# STM32H730xxQ register map
File version: 1.0
Registers are 32-bit, read-write, reset 0x0 unless marked. A register's access mark holds for its fields unless they carry their own. Offsets are from the block's base; [hi:lo] are bit positions; {n}, {i} and the like mark numbered series; 'fields as' and 'values as' point back to an identical list.

## CRYP — Crypto Processor
Base 0x48021000
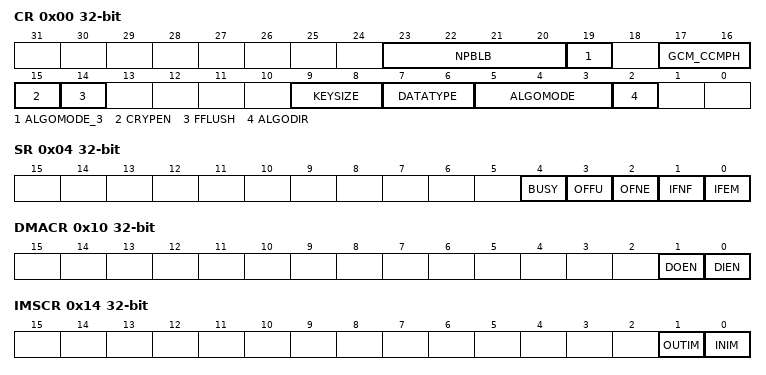
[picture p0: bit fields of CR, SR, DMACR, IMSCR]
0x00 CR — CRYP control register
  [23:20] NPBLB, [19] ALGOMODE_3, [17:16] GCM_CCMPH, [15] CRYPEN, [14] FFLUSH, [9:8] KEYSIZE, [7:6] DATATYPE, [5:3] ALGOMODE, [2] ALGODIR
0x04 SR — CRYP status register
  [4] BUSY, [3] OFFU, [2] OFNE, [1] IFNF, [0] IFEM
0x08 DIN — CRYP data input register
0x0C DOUT — CRYP data output register
0x10 DMACR — CRYP DMA control register
  [1] DOEN, [0] DIEN
0x14 IMSCR — CRYP interrupt mask set/clear register
  [1] OUTIM, [0] INIM
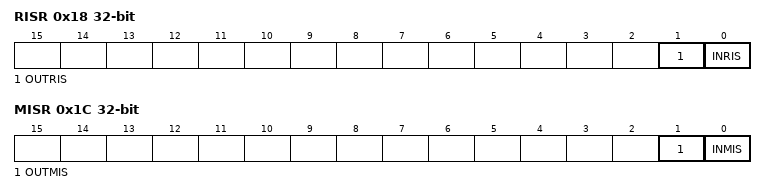
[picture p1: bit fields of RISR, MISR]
0x18 RISR — CRYP raw interrupt status register
  [1] OUTRIS, [0] INRIS
0x1C MISR — CRYP masked interrupt status register
  [1] OUTMIS, [0] INMIS
{0x20+8i} K{i}LR (i=0..3) — CRYP key left register {i}
{0x24+8i} K{i}RR (i=0..3) — CRYP key right register {i}
0x40 IV0LR — CRYP initialization vector left-word register 0
0x44 IV0RR — CRYP initialization vector right-word register 0
0x48 IV1LR — CRYP initialization vector left-word register 1
0x4C IV1RR — CRYP initialization vector right-word register 1
{0x50+4i} CSGCMCCM{i}R (i=0..7) — CRYP GCM/GMAC or CCM/CMAC context swap register {i}
{0x70+4i} CSGCM{i}R (i=0..7) — CRYP GCM/GMAC context swap register {i}

## HASH
Base 0x48021400
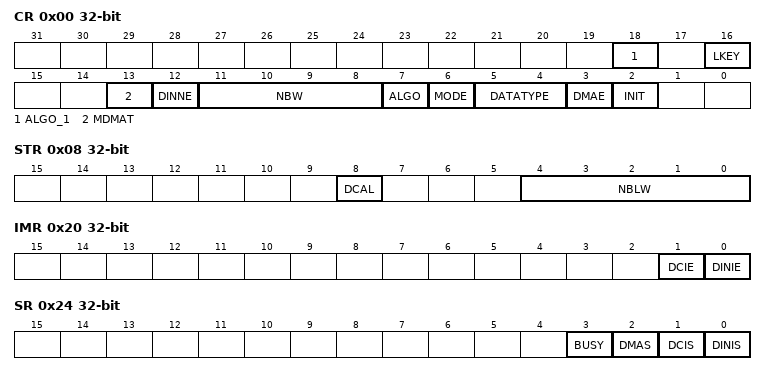
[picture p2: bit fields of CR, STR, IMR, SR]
0x00 CR — HASH control register
  [18] ALGO_1, [16] LKEY, [13] MDMAT, [12] DINNE, [11:8] NBW, [7] ALGO, [6] MODE, [5:4] DATATYPE, [3] DMAE, [2] INIT
0x04 DIN — HASH data input register
0x08 STR — HASH start register
  [8] DCAL, [4:0] NBLW
{0xC+4i} HR{i} (i=0..4) — HASH digest registers
0x20 IMR — HASH interrupt enable register
  [1] DCIE, [0] DINIE
0x24 SR — HASH status register
  [3] BUSY, [2] DMAS, [1] DCIS, [0] DINIS
{0xF8+4i} CSR{i} (i=0..53) — HASH context swap registers
{0x310+4i} DIGEST_HR{i} (i=0..7) — HASH digest registers

## RNG
Base 0x48021800
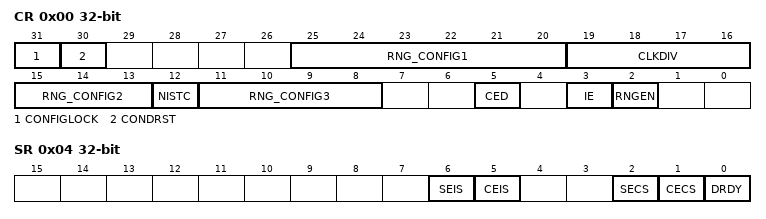
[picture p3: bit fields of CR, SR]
0x00 CR — RNG control register
  [31] CONFIGLOCK
  [30] CONDRST
  [25:20] RNG_CONFIG1
  [19:16] CLKDIV
    0=BY_1 (No clock division); 1=BY_2 (2 RNG clock cycles per internal RNG clock); 2=BY_4 (4 RNG clock cycles per internal RNG clock); 3=BY_8 (8 RNG clock cycles per internal RNG clock); 4=BY_16 (16 RNG clock cycles per internal RNG clock); 5=BY_32 (32 RNG clock cycles per internal RNG clock); 6=BY_64 (64 RNG clock cycles per internal RNG clock); 7=BY_128 (128 RNG clock cycles per internal RNG clock); 8=BY_256 (256 RNG clock cycles per internal RNG clock); 9=BY_512 (512 RNG clock cycles per internal RNG clock); 10=BY_1024 (1024 RNG clock cycles per internal RNG clock); 11=BY_2048 (2048 RNG clock cycles per internal RNG clock); 12=BY_4096 (4096 RNG clock cycles per internal RNG clock); 13=BY_8192 (8192 RNG clock cycles per internal RNG clock); 14=BY_16384 (16384 RNG clock cycles per internal RNG clock); 15=BY_32768 (32768 RNG clock cycles per internal RNG clock)
  [15:13] RNG_CONFIG2
  [12] NISTC
  [11:8] RNG_CONFIG3
  [5] CED
  [3] IE
  [2] RNGEN
0x04 SR — RNG status register
  [6] SEIS, [5] CEIS, [2] SECS, [1] CECS, [0] DRDY
0x08 DR — RNG data register
0x10 HTCR — RNG health test configuration register

## DLYB_SDMMC2 — Delay Block DLYB
Base 0x48022800
Same registers: DLYB_OCTOSPI1 0x52006000, DLYB_SDMMC1 0x52008000, DLYB_OCTOSPI2 0x5200B000
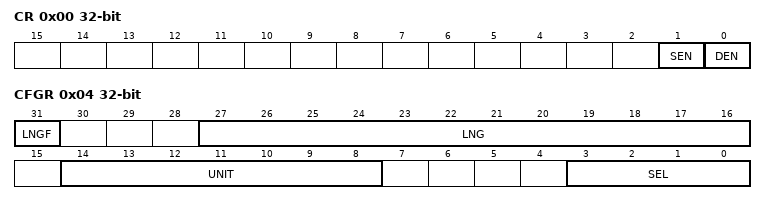
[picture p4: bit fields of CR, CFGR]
0x00 CR — DELAY BLOCK control register
  [1] SEN — Sampler length enable
  [0] DEN — Delay Block enable
0x04 CFGR — DELAY BLOCK configuration register
  [31] LNGF — Length valid flag
  [27:16] LNG — Delay line length value[11:0]
  [14:8] UNIT — Delay Defines the delay of a Unit delay cell[6:0]
  [3:0] SEL — Select the phase for the Output clock[3:0]

## RAMECC2
Base 0x48023000
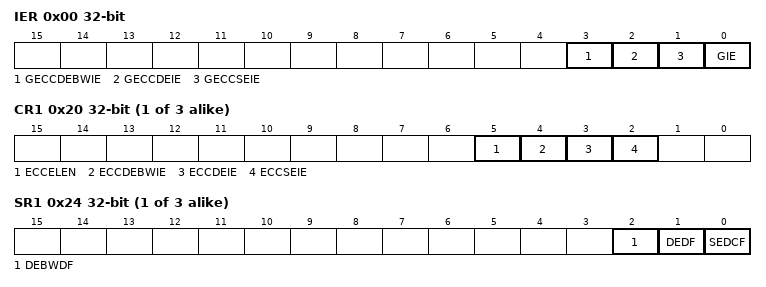
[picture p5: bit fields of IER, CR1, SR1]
0x00 IER — RAMECC interrupt enable register
  [3] GECCDEBWIE — Global ECC double error on byte write (BW) interrupt enable
  [2] GECCDEIE — Global ECC double error interrupt enable
  [1] GECCSEIE — Global ECC single error interrupt enable
  [0] GIE — Global interrupt enable
{0x0+0x20*i} CR{i} (i=1..3) — RAMECC monitor configuration register
  [5] ECCELEN — ECC error latching enable
  [4] ECCDEBWIE — ECC double error on byte write (BW) interrupt enable
  [3] ECCDEIE — ECC double error interrupt enable
  [2] ECCSEIE — ECC single error interrupt enable
{0x4+0x20*i} SR{i} (i=1..3) — RAMECC monitor status register
  [2] DEBWDF — ECC double error on byte write (BW) detected flag
  [1] DEDF — ECC double error detected flag
  [0] SEDCF — ECC single error detected and corrected flag
{0x8+0x20*i} FAR{i} (i=1..3) — RAMECC monitor failing address register
  [31:0] FADD — ECC error failing address
{0xC+0x20*i} FDRL{i} (i=1..3) — RAMECC monitor failing data low register
{0x10+0x20*i} FDRH{i} (i=1..3) — RAMECC monitor failing data high register
{0x14+0x20*i} FECR{i} (i=1..3) — RAMECC monitor failing ECC error code register
  [31:0] FEC — Failing error code

## RAMECC1
Base 0x52009000
Registers as RAMECC2; these are added or differ:
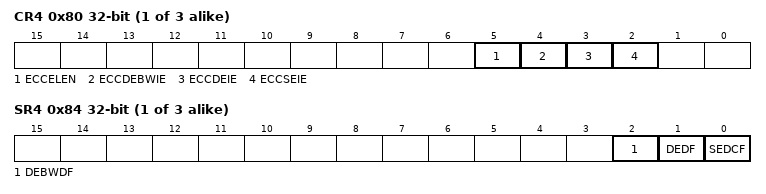
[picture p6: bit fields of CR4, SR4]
{0x0+0x20*i} CR{i} (i=4..6) — RAMECC monitor configuration register
  fields as RAMECC2.CR1
{0x4+0x20*i} SR{i} (i=4..6) — RAMECC monitor status register
  [2] DEBWDF — ECC double error on byte write (BW) detected flag
  [1] DEDF — ECC double error detected flag
  [0] SEDCF — ECC single error detected and corrected flag
{0x8+0x20*i} FAR{i} (i=4..6) — RAMECC monitor failing address register
  [31:0] FADD — ECC error failing address
{0xC+0x20*i} FDRL{i} (i=4..6) — RAMECC monitor failing data low register
{0x10+0x20*i} FDRH{i} (i=4..6) — RAMECC monitor failing data high register
{0x14+0x20*i} FECR{i} (i=4..6) — RAMECC monitor failing ECC error code register
  [31:0] FEC — Failing error code

## RAMECC3
Base 0x58027000
Registers as RAMECC2, without CR3, SR3, FAR3, FDRL3, FDRH3, FECR3.
